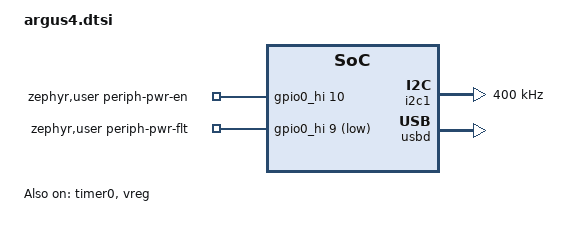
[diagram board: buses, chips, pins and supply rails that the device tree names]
/*
 * Argus 4 CubeSat mainboard: RP2350B (Cortex-M33) on a custom PCB.
 *
 * Pin numbers come from FSW-mainboard/firmware/Mainboard v4/pins.c.
 *
 * Note on GPIO controllers: the RP2350B splits its 48 pins across two
 * controllers. gpio0 covers GPIO0-31, and gpio0_hi covers GPIO32-47 with its
 * own numbering, so GPIO n >= 32 is referenced as <&gpio0_hi (n - 32)>.
 * That offset is the easiest thing to get wrong here.
 *
 * SPDX-License-Identifier: Apache-2.0
 */

#include <freq.h>
#include <zephyr/dt-bindings/i2c/i2c.h>
#include <zephyr/dt-bindings/gpio/gpio.h>

/* W25Q32JVxQ external flash: 32 Mbit = 4 MB. */
#include <raspberrypi/partitions_0x0_default_4M.dtsi>

#include "argus4-pinctrl.dtsi"

/ {
	chosen {
		zephyr,sram = &sram0;
		zephyr,flash = &flash0;
		zephyr,code-partition = &code_partition;
		/* zephyr,console is set to the USB CDC ACM port below: the board
		 * has no debug UART header, so USB is the only console path.
		 */
	};

	aliases {
		watchdog0 = &wdt0;
	};

	/*
	 * Board control lines used directly by flight software rather than by
	 * a Zephyr device driver. Read these with
	 * GPIO_DT_SPEC_GET(DT_PATH(zephyr_user), <name>_gpios).
	 */
	zephyr,user {
		/*
		 * PERIPH_PWR_EN, GPIO42. Gates the peripheral 3.3 V rail that
		 * the MAX17205 fuel gauge and the rest of the I2C devices sit
		 * on. It must be driven high, and given time to settle, before
		 * any I2C transaction: several devices latch their I2C address
		 * at power-up, so probing an unsettled rail can find a device
		 * at the wrong address rather than simply finding nothing.
		 */
		periph-pwr-en-gpios = <&gpio0_hi 10 GPIO_ACTIVE_HIGH>;

		/* PERIPH_PWR_FLT, GPIO41. eFuse overcurrent fault, active low. */
		periph-pwr-flt-gpios = <&gpio0_hi 9 GPIO_ACTIVE_LOW>;
	};
};

&flash0 {
	reg = <0x10000000 DT_SIZE_M(4)>;
	ranges = <0x0 0x10000000 DT_SIZE_M(4)>;
};

/* GPIO0-31 */
&gpio0 {
	status = "okay";
};

/* GPIO32-47: the peripheral power rail and both fuel-gauge bus pins live here. */
&gpio0_hi {
	status = "okay";
};

/*
 * Peripheral I2C bus, SDA1/SCL1 on GPIO46/47. 400 kHz matches the rate the
 * flight-tested Python HAL runs this bus at.
 */
&i2c1 {
	clock-frequency = <I2C_BITRATE_FAST>;
	pinctrl-0 = <&i2c1_default>;
	pinctrl-names = "default";
	status = "okay";
};

/* Secondary I2C bus, SDA0/SCL0 on GPIO24/25. Off until something needs it. */
&i2c0 {
	clock-frequency = <I2C_BITRATE_FAST>;
	pinctrl-0 = <&i2c0_default>;
	pinctrl-names = "default";
	status = "disabled";
};

&uart0 {
	current-speed = <115200>;
	pinctrl-0 = <&uart0_default>;
	pinctrl-names = "default";
	status = "disabled";
};

&timer0 {
	status = "okay";
};

&vreg {
	status = "okay";
};

zephyr_udc0: &usbd {
	status = "okay";
};

/*
 * USB CDC ACM console. This is how the F Prime GDS talks to the board, so it
 * is part of the board definition rather than an application overlay.
 */
&zephyr_udc0 {
	cdc_acm_uart0: cdc_acm_uart0 {
		compatible = "zephyr,cdc-acm-uart";
	};
};

/ {
	chosen {
		zephyr,console = &cdc_acm_uart0;
		zephyr,shell-uart = &cdc_acm_uart0;
	};
};
